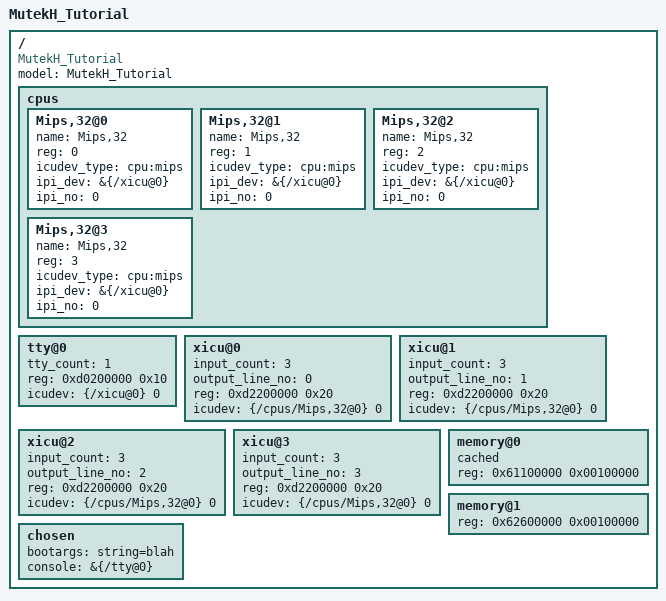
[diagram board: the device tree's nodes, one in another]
/dts-v1/;

/ {
	model = "MutekH_Tutorial";
	compatible = "MutekH_Tutorial";
	#address-cells = <1>;
	#size-cells = <1>;

	cpus {
		#address-cells = <1>;
		#size-cells = <0>;
		Mips,32@0 {
			name = "Mips,32";
			device_type = "cpu";
			reg = <0>;
			icudev_type = "cpu:mips";
			ipi_dev = &{/xicu@0};
			ipi_no = <0>;
		};

		Mips,32@1 {
			name = "Mips,32";
			device_type = "cpu";
			reg = <1>;
			icudev_type = "cpu:mips";
			ipi_dev = &{/xicu@0};
			ipi_no = <0>;
		};

		Mips,32@2 {
			name = "Mips,32";
			device_type = "cpu";
			reg = <2>;
			icudev_type = "cpu:mips";
			ipi_dev = &{/xicu@0};
			ipi_no = <0>;
		};

		Mips,32@3 {
			name = "Mips,32";
			device_type = "cpu";
			reg = <3>;
			icudev_type = "cpu:mips";
			ipi_dev = &{/xicu@0};
			ipi_no = <0>;
		};

	};

	tty@0 {
	    device_type = "soclib:tty";
		tty_count = <1>;
		reg = <0xd0200000 0x10>;
		icudev = <&{/xicu@0} 0>;
	};

	xicu@0 {
	    device_type = "soclib:xicu";
		input_count = <3>;
		output_line_no = <0>;
		reg = <0xd2200000 0x20>;
		icudev = <&{/cpus/Mips,32@0} 0>;
	};

	xicu@1 {
	    device_type = "soclib:xicu";
		input_count = <3>;
		output_line_no = <1>;
		reg = <0xd2200000 0x20>;
		icudev = <&{/cpus/Mips,32@0} 0>;
	};

	xicu@2 {
	    device_type = "soclib:xicu";
		input_count = <3>;
		output_line_no = <2>;
		reg = <0xd2200000 0x20>;
		icudev = <&{/cpus/Mips,32@0} 0>;
	};

	xicu@3 {
	    device_type = "soclib:xicu";
		input_count = <3>;
		output_line_no = <3>;
		reg = <0xd2200000 0x20>;
		icudev = <&{/cpus/Mips,32@0} 0>;
	};

	memory@0 {
		device_type = "memory";
		cached;
		memreg: reg = <0x61100000 0x00100000>;
	};

	memory@1 {
		device_type = "memory";
		memreg: reg = <0x62600000 0x00100000>;
	};

	chosen {
		bootargs = "string=blah";
		console = &{/tty@0};
	};

};
